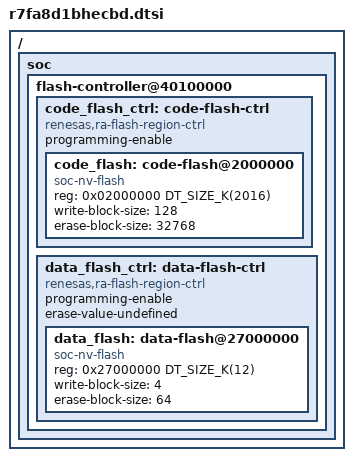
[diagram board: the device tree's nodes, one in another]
/*
 * Copyright (c) 2024-2026 Renesas Electronics Corporation
 *
 * SPDX-License-Identifier: Apache-2.0
 */

#include <arm/renesas/ra/ra8/r7fa8d1xh.dtsi>
#include <zephyr/dt-bindings/mipi_dsi/mipi_dsi.h>

/ {
	soc {
		flash-controller@40100000 {
			code_flash_ctrl: code-flash-ctrl {
				compatible = "renesas,ra-flash-region-ctrl";
				programming-enable;
				#address-cells = <1>;
				#size-cells = <1>;

				code_flash: code-flash@2000000 {
					compatible = "soc-nv-flash";
					reg = <0x02000000 DT_SIZE_K(2016)>;
					ranges = <0x0 0x02000000 DT_SIZE_K(2016)>;
					write-block-size = <128>;
					erase-block-size = <32768>;
					#address-cells = <1>;
					#size-cells = <1>;
				};
			};

			data_flash_ctrl: data-flash-ctrl {
				compatible = "renesas,ra-flash-region-ctrl";
				programming-enable;
				erase-value-undefined;
				#address-cells = <1>;
				#size-cells = <1>;

				data_flash: data-flash@27000000 {
					compatible = "soc-nv-flash";
					reg = <0x27000000 DT_SIZE_K(12)>;
					ranges = <0x0 0x27000000 DT_SIZE_K(12)>;
					write-block-size = <4>;
					erase-block-size = <64>;
					#address-cells = <1>;
					#size-cells = <1>;
				};
			};
		};
	};
};
